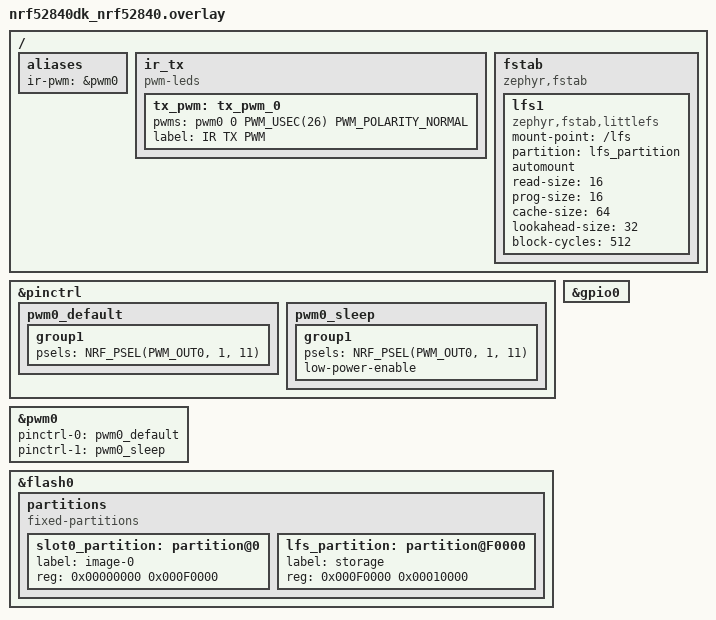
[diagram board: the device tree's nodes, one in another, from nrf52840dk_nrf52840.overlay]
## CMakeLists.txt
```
# CMakeLists.txt for IR Remote Control Project

cmake_minimum_required(VERSION 3.20.0)

find_package(Zephyr REQUIRED HINTS $ENV{ZEPHYR_BASE})
project(ir_remote_control)

# 包含目录
target_include_directories(app PRIVATE
    ${CMAKE_CURRENT_SOURCE_DIR}/include
)

# 源文件
target_sources(app PRIVATE
    src/main.c
    src/ir_hal.c
    src/irdb_protocol.c
    src/irdb_loader.c
    src/ir_service.c
    src/ir_learning.c
)

# 如果有Shell支持，添加学习应用示例
if(CONFIG_SHELL)
    target_sources(app PRIVATE
        src/ir_learning_app.c
    )
endif()
```

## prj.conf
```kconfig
#
# prj.conf - Zephyr项目配置
#

# 基本配置
CONFIG_HEAP_MEM_POOL_SIZE=16384
CONFIG_MAIN_STACK_SIZE=4096
CONFIG_SYSTEM_WORKQUEUE_STACK_SIZE=2048

# GPIO支持
CONFIG_GPIO=y

# PWM支持
CONFIG_PWM=y

# 日志系统
CONFIG_LOG=y
CONFIG_LOG_MODE_IMMEDIATE=y
CONFIG_PRINTK=y
CONFIG_CONSOLE=y
CONFIG_UART_CONSOLE=y

# 调试支持
CONFIG_DEBUG=y
CONFIG_DEBUG_INFO=y
CONFIG_ASSERT=y

# Shell命令行
CONFIG_SHELL=y
CONFIG_SHELL_BACKEND_SERIAL=y
CONFIG_SHELL_PROMPT_UART="ir> "
CONFIG_SHELL_CMD_BUFF_SIZE=128
CONFIG_SHELL_PRINTF_BUFF_SIZE=128

# 浮点数支持
CONFIG_FPU=y

# 动态内存分配
CONFIG_HEAP_MEM_POOL_SIZE=16384

# 文件系统支持（完整配置）
CONFIG_FILE_SYSTEM=y
CONFIG_FILE_SYSTEM_LITTLEFS=y

# Flash驱动支持（LittleFS需要）
CONFIG_FLASH=y
CONFIG_FLASH_MAP=y
CONFIG_FLASH_PAGE_LAYOUT=y

# NVS存储支持（替代方案，推荐用于简单存储）
CONFIG_NVS=y
CONFIG_MPU_ALLOW_FLASH_WRITE=y

# 网络支持（可选，默认禁用）
# CONFIG_NETWORKING=y
# CONFIG_NET_SOCKETS=y
# CONFIG_HTTP_CLIENT=y
```

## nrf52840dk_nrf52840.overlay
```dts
/*
 * nRF52840 IR设备树配置
 * 文件名: nrf52840dk_nrf52840.overlay
 */

/ {
    aliases {
        ir-pwm = &pwm0;
    };
    
    ir_tx: ir_tx {
        compatible = "pwm-leds";
        status = "okay";
        tx_pwm: tx_pwm_0 {
            pwms = <&pwm0 0 PWM_USEC(26) PWM_POLARITY_NORMAL>;
            label = "IR TX PWM";
        };
    };
    
    /* LittleFS挂载配置 */
    fstab {
        compatible = "zephyr,fstab";
        lfs1: lfs1 {
            compatible = "zephyr,fstab,littlefs";
            mount-point = "/lfs";
            partition = <&lfs_partition>;
            automount;
            read-size = <16>;
            prog-size = <16>;
            cache-size = <64>;
            lookahead-size = <32>;
            block-cycles = <512>;
        };
    };
};

&pinctrl {
    pwm0_default: pwm0_default {
        group1 {
            psels = <NRF_PSEL(PWM_OUT0, 1, 11)>;
        };
    };

    pwm0_sleep: pwm0_sleep {
        group1 {
            psels = <NRF_PSEL(PWM_OUT0, 1, 11)>;
            low-power-enable;
        };
    };
};

&pwm0 {
    status = "okay";
    pinctrl-0 = <&pwm0_default>;
    pinctrl-1 = <&pwm0_sleep>;
    pinctrl-names = "default", "sleep";
};

&gpio0 {
    status = "okay";
};

/* 删除现有的分区定义，重新定义 */
/delete-node/ &boot_partition;
/delete-node/ &slot0_partition;
/delete-node/ &slot1_partition;
/delete-node/ &storage_partition;

/* Flash分区配置 - 简化版本，不使用MCUboot */
&flash0 {
    partitions {
        compatible = "fixed-partitions";
        #address-cells = <1>;
        #size-cells = <1>;

        /* 应用程序区域 */
        slot0_partition: partition@0 {
            label = "image-0";
            reg = <0x00000000 0x000F0000>;  /* 960KB 用于应用 */
        };

        /* LittleFS存储分区 */
        lfs_partition: partition@F0000 {
            label = "storage";
            reg = <0x000F0000 0x00010000>;  /* 64KB 用于文件系统 */
        };
    };
};
```

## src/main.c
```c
/**
 * @file main.c
 * @brief IR遥控应用 - 使用IRDB数据库 + 自学习功能
 */

#include "ir_learning.h"
#include "ir_service.h"
#include <stdlib.h> // 添加：atoi
#include <string.h> // 添加：strcmp, strcpy
#include <zephyr/kernel.h>
#include <zephyr/logging/log.h>


LOG_MODULE_REGISTER(ir_app, LOG_LEVEL_INF);

/* Zephyr已经定义了ARRAY_SIZE，不需要重复定义 */

/* 嵌入式IRDB数据 - Samsung TV (7,7) */
static const char samsung_tv_7_7[] = "Power,1,7,7,2\n"
                                     "Source,1,7,7,1\n"
                                     "Menu,1,7,7,26\n"
                                     "Up,1,7,7,96\n"
                                     "Down,1,7,7,97\n"
                                     "Left,1,7,7,101\n"
                                     "Right,1,7,7,98\n"
                                     "Enter,1,7,7,104\n"
                                     "Back,1,7,7,88\n"
                                     "Vol+,1,7,7,7\n"
                                     "Vol-,1,7,7,11\n"
                                     "Mute,1,7,7,15\n"
                                     "Ch+,1,7,7,18\n"
                                     "Ch-,1,7,7,16\n"
                                     "1,1,7,7,4\n"
                                     "2,1,7,7,5\n"
                                     "3,1,7,7,6\n"
                                     "4,1,7,7,8\n"
                                     "5,1,7,7,9\n"
                                     "6,1,7,7,10\n"
                                     "7,1,7,7,12\n"
                                     "8,1,7,7,13\n"
                                     "9,1,7,7,14\n"
                                     "0,1,7,7,17\n";

/* Sony TV IRDB数据 */
static const char sony_tv[] = "Power,15,1,0,21\n"
                              "Vol+,15,1,0,18\n"
                              "Vol-,15,1,0,19\n"
                              "Ch+,15,1,0,16\n"
                              "Ch-,15,1,0,17\n"
                              "Mute,15,1,0,20\n"
                              "Input,15,1,0,37\n"
                              "1,15,1,0,0\n"
                              "2,15,1,0,1\n"
                              "3,15,1,0,2\n"
                              "4,15,1,0,3\n"
                              "5,15,1,0,4\n"
                              "6,15,1,0,5\n"
                              "7,15,1,0,6\n"
                              "8,15,1,0,7\n"
                              "9,15,1,0,8\n"
                              "0,15,1,0,9\n";

/* 接收回调 */
static void rx_callback(const irdb_entry_t *entry, void *user_data) {
  LOG_INF("Received: %s", entry->function_name);
  LOG_INF("  Protocol: %u, Device: %u.%u, Function: %u", entry->protocol,
          entry->device, entry->subdevice, entry->function);

  /* 根据接收到的命令执行操作 */
  if (strcmp(entry->function_name, "Power") == 0) {
    LOG_INF(">> Power button action");
  } else if (strcmp(entry->function_name, "Vol+") == 0) {
    LOG_INF(">> Volume up action");
  } else if (strcmp(entry->function_name, "Vol-") == 0) {
    LOG_INF(">> Volume down action");
  }
}

/* 发送测试 */
static void test_send(void) {
  LOG_INF("=== Send Test ===");

  const char *test_commands[] = {"Power", "Vol+", "Vol-", "Ch+", "Mute"};

  for (int i = 0; i < ARRAY_SIZE(test_commands); i++) {
    LOG_INF("Sending: %s", test_commands[i]);

    int ret = ir_service_send_command(test_commands[i], 1);
    if (ret < 0) {
      LOG_ERR("Failed to send %s: %d", test_commands[i], ret);
    }

    k_sleep(K_MSEC(500));
  }
}

/* 接收测试 */
static void test_receive(uint32_t duration_sec) {
  LOG_INF("=== Receive Test ===");
  LOG_INF("Point remote at receiver and press buttons...");

  int ret = ir_service_start_receive(rx_callback, NULL);
  if (ret < 0) {
    LOG_ERR("Failed to start receive: %d", ret);
    return;
  }

  k_sleep(K_SECONDS(duration_sec));

  ir_service_stop_receive();
  LOG_INF("Receive test completed");
}

/* 主函数 */
int main(void) {
  LOG_INF("========================================");
  LOG_INF("  IR Remote Control with IRDB");
  LOG_INF("  + Self-Learning Feature");
  LOG_INF("  nRF52840 + Zephyr RTOS");
  LOG_INF("========================================");

  /* 初始化服务 */
  int ret = ir_service_init();
  if (ret < 0) {
    LOG_ERR("Service init failed: %d", ret);
    return ret;
  }

  /* 初始化学习模块 */
  ret = ir_learning_init();
  if (ret < 0) {
    LOG_ERR("Learning init failed: %d", ret);
    return ret;
  }

  /* 方式1: 从嵌入式数据加载 */
  LOG_INF("Loading Samsung TV database (embedded)...");
  ret = ir_service_load_embedded_csv(samsung_tv_7_7, "Samsung", "TV");
  if (ret < 0) {
    LOG_ERR("Failed to load database: %d", ret);
    return ret;
  }

  /* 显示数据库信息 */
  char list_buf[1024];
  ir_service_list_functions(list_buf, sizeof(list_buf));
  LOG_INF("\n%s", list_buf);

  k_sleep(K_SECONDS(2));

  /* 运行测试 */
  while (1) {
    LOG_INF("\n>>> Test Cycle Start <<<\n");

    /* 发送测试 */
    test_send();
    k_sleep(K_SECONDS(2));

    /* 接收测试 */
    test_receive(30);
    k_sleep(K_SECONDS(2));

    LOG_INF("\n>>> Test Cycle Complete <<<\n");

/* 可选: 切换到Sony遥控器 */
#if 0
        LOG_INF("Switching to Sony TV database...");
        ir_service_load_embedded_csv(sony_tv, "Sony", "TV");
        ir_service_list_functions(list_buf, sizeof(list_buf));
        LOG_INF("\n%s", list_buf);
#endif
  }

  return 0;
}

/* Shell命令接口 */
#ifdef CONFIG_SHELL

#include <zephyr/shell/shell.h>

/* 加载数据库命令 */
static int cmd_load(const struct shell *shell, size_t argc, char **argv) {
  if (argc < 2) {
    shell_error(shell, "Usage: ir load <samsung|sony>");
    return -EINVAL;
  }

  int ret;
  if (strcmp(argv[1], "samsung") == 0) {
    ret = ir_service_load_embedded_csv(samsung_tv_7_7, "Samsung", "TV");
  } else if (strcmp(argv[1], "sony") == 0) {
    ret = ir_service_load_embedded_csv(sony_tv, "Sony", "TV");
  } else {
    shell_error(shell, "Unknown remote: %s", argv[1]);
    return -EINVAL;
  }

  if (ret == 0) {
    shell_print(shell, "Database loaded successfully");
  } else {
    shell_error(shell, "Failed to load: %d", ret);
  }

  return ret;
}

/* 发送命令 */
static int cmd_send(const struct shell *shell, size_t argc, char **argv) {
  if (argc < 2) {
    shell_error(shell, "Usage: ir send <function> [repeat]");
    return -EINVAL;
  }

  const char *function = argv[1];
  uint32_t repeat = argc > 2 ? atoi(argv[2]) : 1;

  shell_print(shell, "Sending: %s (x%u)", function, repeat);

  int ret = ir_service_send_command(function, repeat);
  if (ret < 0) {
    shell_error(shell, "Send failed: %d", ret);
    return ret;
  }

  shell_print(shell, "Sent successfully");
  return 0;
}

/* 接收命令 */
static int cmd_receive(const struct shell *shell, size_t argc, char **argv) {
  uint32_t duration = argc > 1 ? atoi(argv[1]) : 10;

  shell_print(shell, "Receiving for %u seconds...", duration);

  int ret = ir_service_start_receive(rx_callback, NULL);
  if (ret < 0) {
    shell_error(shell, "Failed to start: %d", ret);
    return ret;
  }

  k_sleep(K_SECONDS(duration));
  ir_service_stop_receive();

  shell_print(shell, "Receive completed");
  return 0;
}

/* 列出功能 */
static int cmd_list(const struct shell *shell, size_t argc, char **argv) {
  char buf[1024];

  int ret = ir_service_list_functions(buf, sizeof(buf));
  if (ret < 0) {
    shell_error(shell, "No database loaded");
    return ret;
  }

  shell_print(shell, "%s", buf);
  return 0;
}

/* 从文件加载（需要文件系统支持） */
#ifdef CONFIG_FILE_SYSTEM
static int cmd_load_file(const struct shell *shell, size_t argc, char **argv) {
  if (argc < 4) {
    shell_error(
        shell,
        "Usage: ir loadfile <manufacturer> <device_type> <device,subdevice>");
    shell_error(shell, "Example: ir loadfile Samsung TV 7,7");
    return -EINVAL;
  }

  const char *manufacturer = argv[1];
  const char *device_type = argv[2];

  uint8_t device, subdevice;
  if (sscanf(argv[3], "%hhu,%hhu", &device, &subdevice) != 2) {
    shell_error(shell, "Invalid device,subdevice format");
    return -EINVAL;
  }

  ir_service_config_t config = {.load_method = IRDB_LOAD_FILESYSTEM,
                                .device = device,
                                .subdevice = subdevice};

  strncpy(config.manufacturer, manufacturer, sizeof(config.manufacturer) - 1);
  strncpy(config.device_type, device_type, sizeof(config.device_type) - 1);

  shell_print(shell, "Loading: %s/%s/%u,%u.csv", manufacturer, device_type,
              device, subdevice);

  int ret = ir_service_load_remote(&config);
  if (ret < 0) {
    shell_error(shell, "Load failed: %d", ret);
    return ret;
  }

  shell_print(shell, "Loaded successfully");
  return 0;
}
#endif

SHELL_STATIC_SUBCMD_SET_CREATE(
    ir_cmds, SHELL_CMD(load, NULL, "Load embedded database", cmd_load),
    SHELL_CMD(send, NULL, "Send IR command", cmd_send),
    SHELL_CMD(receive, NULL, "Receive IR signals", cmd_receive),
    SHELL_CMD(list, NULL, "List functions", cmd_list),
#ifdef CONFIG_FILE_SYSTEM
    SHELL_CMD(loadfile, NULL, "Load from file", cmd_load_file),
#endif
    SHELL_SUBCMD_SET_END);

SHELL_CMD_REGISTER(ir, &ir_cmds, "IR remote control (IRDB)", NULL);

#endif /* CONFIG_SHELL */
```

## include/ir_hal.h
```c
/**
 * @file ir_hal.h
 * @brief IR硬件抽象层 - nRF52840
 */

#ifndef IR_HAL_H
#define IR_HAL_H

#include <zephyr/device.h>
#include <zephyr/drivers/gpio.h>
#include <zephyr/drivers/pwm.h>
#include <zephyr/kernel.h>

/* 配置参数 */
#define IR_TX_NODE DT_NODELABEL(tx_pwm)
#define IR_RX_PIN 12           // P0.14 用于IR接收
#define IR_CARRIER_FREQ 38000  // 38kHz载波
#define IR_PWM_DUTY 33         // 33%占空比
#define IR_MAX_PULSE_US 100000 // 最大脉冲宽度100ms
#define IR_TIMER_FREQ 1000000  // 1MHz定时器频率

/* IR脉冲结构 */
typedef struct {
  uint32_t duration_us; // 持续时间(微秒)
  bool is_mark;         // true=mark(载波), false=space(无载波)
} ir_pulse_t;

/* IR接收回调 */
typedef void (*ir_rx_callback_t)(ir_pulse_t *pulse, void *user_data);

/* HAL初始化 */
int ir_hal_init(void);

/* 发送接口 */
int ir_hal_tx_start(uint32_t carrier_freq);
int ir_hal_tx_stop(void);
int ir_hal_tx_pulse(uint32_t duration_us, bool is_mark);

/* 接收接口 */
int ir_hal_rx_start(ir_rx_callback_t callback, void *user_data);
int ir_hal_rx_stop(void);

#endif /* IR_HAL_H */
```

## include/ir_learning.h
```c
/**
 * @file ir_learning.h
 * @brief IR自学习模块 - 录制和重放任意红外信号
 */

#ifndef IR_LEARNING_H
#define IR_LEARNING_H

#include <stdbool.h>
#include <stddef.h>
#include <stdint.h>

/* 学习的信号最大长度 */
#define IR_LEARNING_MAX_EDGES 512
#define IR_LEARNING_MAX_DURATION_US 100000

/* 学习信号结构 */
typedef struct {
  char name[32];              // 信号名称
  uint32_t *timings;          // 时序数据数组 (微秒)
  uint16_t timing_count;      // 时序数量
  uint32_t carrier_freq;      // 检测到的载波频率
  uint32_t total_duration_us; // 总时长
  bool valid;                 // 是否有效
} ir_learned_signal_t;

/* 学习回调 - 学习过程中的状态通知 */
typedef enum {
  IR_LEARN_IDLE,      // 空闲
  IR_LEARN_WAITING,   // 等待信号
  IR_LEARN_RECEIVING, // 接收中
  IR_LEARN_COMPLETED, // 完成
  IR_LEARN_TIMEOUT,   // 超时
  IR_LEARN_ERROR      // 错误
} ir_learn_status_t;

typedef void (*ir_learn_callback_t)(ir_learn_status_t status,
                                    const ir_learned_signal_t *signal,
                                    void *user_data);

/* 初始化学习模块 */
int ir_learning_init(void);

/* 开始学习模式 */
int ir_learning_start(const char *signal_name, ir_learn_callback_t callback,
                      void *user_data, uint32_t timeout_ms);

/* 停止学习 */
int ir_learning_stop(void);

/* 重放学习的信号 */
int ir_learning_replay(const ir_learned_signal_t *signal,
                       uint32_t repeat_count);

/* 保存学习的信号到存储 */
int ir_learning_save(const ir_learned_signal_t *signal, const char *name);

/* 从存储加载信号 */
int ir_learning_load(ir_learned_signal_t *signal, const char *name);

/* 删除已保存的信号 */
int ir_learning_delete(const char *name);

/* 列出所有已保存的信号 */
int ir_learning_list(char *buf, size_t buf_size);

/* 导出为原始格式 (用于调试) */
int ir_learning_export_raw(const ir_learned_signal_t *signal, char *buf,
                           size_t buf_size);

/* 从原始格式导入 */
int ir_learning_import_raw(ir_learned_signal_t *signal, const char *raw_data);

void test_ir_learning(void);

/* 分析信号特征 */
typedef struct {
  uint32_t avg_mark;       // 平均mark时长
  uint32_t avg_space;      // 平均space时长
  uint32_t min_pulse;      // 最短脉冲
  uint32_t max_pulse;      // 最长脉冲
  uint32_t pulse_count;    // 脉冲数量
  uint32_t estimated_freq; // 估计的载波频率
} ir_signal_analysis_t;

int ir_learning_analyze(const ir_learned_signal_t *signal,
                        ir_signal_analysis_t *analysis);

/* 比较两个信号的相似度 (0-100%) */
int ir_learning_compare(const ir_learned_signal_t *sig1,
                        const ir_learned_signal_t *sig2, uint8_t *similarity);

#endif /* IR_LEARNING_H */
```

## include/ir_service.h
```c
/**
 * @file ir_service.h
 * @brief IR服务层 - 整合HAL、IRDB协议和加载器
 */

#ifndef IR_SERVICE_H
#define IR_SERVICE_H

#include "ir_hal.h"
#include "irdb_loader.h"
#include "irdb_protocol.h"
#include <stddef.h>


/* IR服务配置 */
typedef struct {
  irdb_load_method_t load_method;
  char manufacturer[64];
  char device_type[64];
  uint8_t device;
  uint8_t subdevice;
} ir_service_config_t;

/* IR服务初始化 */
int ir_service_init(void);

/* 加载遥控器数据库 */
int ir_service_load_remote(const ir_service_config_t *config);

/* 从嵌入式数据加载 */
int ir_service_load_embedded_csv(const char *csv_data, const char *manufacturer,
                                 const char *device_type);

/* 发送命令（通过功能名） */
int ir_service_send_command(const char *function_name, uint32_t repeat);

/* 发送原始IRDB条目 */
int ir_service_send_entry(const irdb_entry_t *entry, uint32_t repeat);

/* 接收回调 */
typedef void (*ir_service_rx_callback_t)(const irdb_entry_t *entry,
                                         void *user_data);

/* 启动接收 */
int ir_service_start_receive(ir_service_rx_callback_t callback,
                             void *user_data);

/* 停止接收 */
int ir_service_stop_receive(void);

/* 列出当前数据库的所有功能 */
int ir_service_list_functions(char *buf, size_t buf_size);

/* 获取当前数据库信息 */
const irdb_database_t *ir_service_get_database(void);

#endif /* IR_SERVICE_H */
```

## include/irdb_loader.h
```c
/**
 * @file irdb_loader.h
 * @brief IRDB数据加载器 - 支持多种加载方式
 */

#ifndef IRDB_LOADER_H
#define IRDB_LOADER_H

#include "irdb_protocol.h"
#include <stddef.h>


/* 加载方式 */
typedef enum {
  IRDB_LOAD_EMBEDDED,   // 嵌入式存储（编译时包含）
  IRDB_LOAD_FILESYSTEM, // 从文件系统加载
  IRDB_LOAD_HTTP,       // 从HTTP服务器加载（需要网络）
  IRDB_LOAD_EXTERNAL,   // 外部存储（SD卡等）
} irdb_load_method_t;

/* IRDB路径构建 */
void irdb_build_path(char *path_out, size_t path_size, const char *manufacturer,
                     const char *device_type, uint8_t device,
                     uint8_t subdevice);

/* 从嵌入式数据加载 */
int irdb_load_embedded(irdb_database_t *db, const char *csv_data);

/* 从文件系统加载 */
int irdb_load_from_file(irdb_database_t *db, const char *filepath);

/* 从HTTP加载（需要网络支持） */
int irdb_load_from_http(irdb_database_t *db, const char *manufacturer,
                        const char *device_type, uint8_t device,
                        uint8_t subdevice);

/* 缓存管理 */
typedef struct {
  char path[128];
  irdb_database_t database;
  uint32_t last_access;
  bool valid;
} irdb_cache_entry_t;

#define IRDB_CACHE_SIZE 4

int irdb_cache_get(const char *path, irdb_database_t **db_out);
int irdb_cache_put(const char *path, const irdb_database_t *db);
void irdb_cache_clear(void);

#endif /* IRDB_LOADER_H */
```

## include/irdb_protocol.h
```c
/**
 * @file irdb_protocol.h
 * @brief IRDB协议定义和CSV解析器
 *
 * IRDB使用 protocol,device,subdevice,function 格式存储IR码
 */

#ifndef IRDB_PROTOCOL_H
#define IRDB_PROTOCOL_H

#include <stdbool.h>
#include <stdint.h>


/* IRDB协议编号 */
typedef enum {
  IRDB_PROTOCOL_NEC1 = 1,
  IRDB_PROTOCOL_NEC2 = 2,
  IRDB_PROTOCOL_RC5 = 4,
  IRDB_PROTOCOL_RC6 = 5,
  IRDB_PROTOCOL_SONY12 = 15,
  IRDB_PROTOCOL_SONY15 = 16,
  IRDB_PROTOCOL_SONY20 = 17,
  IRDB_PROTOCOL_SAMSUNG32 = 20,
  IRDB_PROTOCOL_SAMSUNG36 = 21,
} irdb_protocol_id_t;

/* IRDB条目 */
typedef struct {
  char function_name[32]; // 功能名称 (如 "Power", "Vol+")
  uint16_t protocol;      // 协议编号
  uint16_t device;        // 设备码
  uint16_t subdevice;     // 子设备码
  uint16_t function;      // 功能码
} irdb_entry_t;

/* IRDB数据库 */
typedef struct {
  char manufacturer[64]; // 制造商
  char device_type[64];  // 设备类型
  irdb_entry_t *entries; // 条目数组
  uint32_t entry_count;  // 条目数量
} irdb_database_t;

/* 协议参数表 */
typedef struct {
  irdb_protocol_id_t protocol_id;
  const char *name;
  uint32_t frequency;     // 载波频率(Hz)
  uint32_t duty_cycle;    // 占空比(%)
  uint32_t header_mark;   // 引导标记(us)
  uint32_t header_space;  // 引导间隔(us)
  uint32_t bit_mark;      // 位标记(us)
  uint32_t bit_0_space;   // 0位间隔(us)
  uint32_t bit_1_space;   // 1位间隔(us)
  uint32_t trailer_mark;  // 结束标记(us)
  uint32_t gap;           // 重复间隔(us)
  uint8_t device_bits;    // 设备码位数
  uint8_t subdevice_bits; // 子设备码位数
  uint8_t function_bits;  // 功能码位数
  bool toggle_bit;        // 是否有toggle位
} irdb_protocol_params_t;

/* 协议参数查询 */
const irdb_protocol_params_t *
irdb_get_protocol_params(irdb_protocol_id_t protocol);

/* CSV解析 */
int irdb_parse_csv(const char *csv_data, irdb_database_t *db);

/* 释放数据库 */
void irdb_free_database(irdb_database_t *db);

/* 查找功能 */
const irdb_entry_t *irdb_find_function(const irdb_database_t *db,
                                       const char *function_name);

/* 编码为原始数据 */
int irdb_encode_to_raw(const irdb_entry_t *entry, uint32_t *timings_out,
                       uint32_t *length_out, uint32_t max_length);

/* 解码原始数据 */
int irdb_decode_from_raw(const irdb_database_t *db, const uint32_t *timings,
                         uint32_t length, irdb_entry_t *entry_out);

#endif /* IRDB_PROTOCOL_H */
```

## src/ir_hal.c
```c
/**
 * @file ir_hal.c
 * @brief IR硬件抽象层实现 - nRF52840
 */

#include "ir_hal.h"
#include <zephyr/drivers/gpio.h>
#include <zephyr/logging/log.h>

LOG_MODULE_REGISTER(ir_hal, LOG_LEVEL_INF);

/* PWM设备 */
static const struct pwm_dt_spec pwm_ir = PWM_DT_SPEC_GET(IR_TX_NODE);

/* GPIO设备 - 使用设备树方式获取 */
#define RX_GPIO_NODE DT_NODELABEL(gpio1)
static const struct device *gpio_dev = DEVICE_DT_GET(RX_GPIO_NODE);

/* GPIO回调结构 */
static struct gpio_callback gpio_cb;

/* 接收状态 */
static struct {
  ir_rx_callback_t callback;
  void *user_data;
  uint32_t last_edge_us;
  bool last_state;
  bool active;
} rx_state;

/* GPIO中断处理 - 接收边沿检测 */
static void gpio_callback_handler(const struct device *dev,
                                  struct gpio_callback *cb, uint32_t pins) {
  /* 安全检查 */
  if (!rx_state.active) {
    return;
  }

  if (!dev || dev != gpio_dev) {
    return;
  }

  uint32_t now_us = k_cyc_to_us_floor32(k_cycle_get_32());
  int current_state = gpio_pin_get(gpio_dev, IR_RX_PIN);

  /* 检查GPIO读取是否成功 */
  if (current_state < 0) {
    return;
  }

  if (rx_state.last_edge_us > 0) {
    uint32_t duration;

    /* 处理32位计数器溢出 */
    if (now_us >= rx_state.last_edge_us) {
      duration = now_us - rx_state.last_edge_us;
    } else {
      /* 溢出情况 */
      duration = (UINT32_MAX - rx_state.last_edge_us) + now_us + 1;
    }

    if (duration > 0 && duration < IR_MAX_PULSE_US) {
      ir_pulse_t pulse = {
          .duration_us = duration,
          .is_mark = !rx_state.last_state // 上一个状态
      };

      if (rx_state.callback) {
        rx_state.callback(&pulse, rx_state.user_data);
      }
    }
  }

  rx_state.last_edge_us = now_us;
  rx_state.last_state = (current_state != 0);
}

/* HAL初始化 */
int ir_hal_init(void) {
  int ret;

  LOG_INF("Initializing IR HAL...");

  /* 检查PWM设备 */
  if (!device_is_ready(pwm_ir.dev)) {
    LOG_ERR("PWM device not ready");
    return -ENODEV;
  }
  LOG_DBG("PWM device ready");

  /* 检查GPIO设备 */
  if (!gpio_dev) {
    LOG_ERR("GPIO device is NULL");
    return -ENODEV;
  }

  if (!device_is_ready(gpio_dev)) {
    LOG_ERR("GPIO device not ready");
    return -ENODEV;
  }
  LOG_DBG("GPIO device ready");

  /* 配置RX GPIO为输入，带上拉 */
  ret = gpio_pin_configure(gpio_dev, IR_RX_PIN, GPIO_INPUT | GPIO_PULL_UP);
  if (ret < 0) {
    LOG_ERR("Failed to configure RX pin %d: %d", IR_RX_PIN, ret);
    return ret;
  }
  LOG_DBG("RX pin %d configured", IR_RX_PIN);

  /* 禁用GPIO中断（初始状态） */
  ret = gpio_pin_interrupt_configure(gpio_dev, IR_RX_PIN, GPIO_INT_DISABLE);
  if (ret < 0) {
    LOG_ERR("Failed to configure interrupt: %d", ret);
    return ret;
  }

  /* 初始化GPIO回调 */
  gpio_init_callback(&gpio_cb, gpio_callback_handler, BIT(IR_RX_PIN));

  ret = gpio_add_callback(gpio_dev, &gpio_cb);
  if (ret < 0) {
    LOG_ERR("Failed to add callback: %d", ret);
    return ret;
  }
  LOG_DBG("GPIO callback added");

  /* 初始化接收状态 */
  memset(&rx_state, 0, sizeof(rx_state));

  /* 确保PWM初始关闭 */
  ret = pwm_set_dt(&pwm_ir, 0, 0);
  if (ret < 0) {
    LOG_WRN("Failed to stop PWM initially: %d", ret);
  }

  LOG_INF("IR HAL initialized successfully");
  return 0;
}

/* 启动发送 - 配置载波频率 */
int ir_hal_tx_start(uint32_t carrier_freq) {
  uint32_t period_ns = NSEC_PER_SEC / carrier_freq;
  uint32_t pulse_ns = period_ns * IR_PWM_DUTY / 100;

  int ret = pwm_set_dt(&pwm_ir, period_ns, pulse_ns);
  if (ret < 0) {
    LOG_ERR("Failed to start PWM: %d", ret);
    return ret;
  }

  LOG_DBG("TX started: %u Hz", carrier_freq);
  return 0;
}

/* 停止发送 */
int ir_hal_tx_stop(void) {
  pwm_set_dt(&pwm_ir, 0, 0);
  LOG_DBG("TX stopped");
  return 0;
}

/* 发送单个脉冲 */
int ir_hal_tx_pulse(uint32_t duration_us, bool is_mark) {
  if (is_mark) {
    /* Mark: 恢复PWM输出 - 不需要重新配置，PWM保持运行 */
    /* nRF52840 PWM特性：一旦配置就持续输出 */
  } else {
    /* Space: 暂时禁用PWM */
    pwm_set_dt(&pwm_ir, 0, 0);
  }

  k_busy_wait(duration_us);

  /* 如果是space后，恢复PWM为下一个mark做准备 */
  if (!is_mark) {
    uint32_t period_ns = NSEC_PER_SEC / IR_CARRIER_FREQ;
    uint32_t pulse_ns = period_ns * IR_PWM_DUTY / 100;
    pwm_set_dt(&pwm_ir, period_ns, pulse_ns);
  }

  return 0;
}

/* 启动接收 */
int ir_hal_rx_start(ir_rx_callback_t callback, void *user_data) {
  if (!callback) {
    return -EINVAL;
  }

  rx_state.callback = callback;
  rx_state.user_data = user_data;
  rx_state.last_edge_us = 0;
  rx_state.last_state = false;
  rx_state.active = true;

  /* 启用双边沿中断 */
  int ret =
      gpio_pin_interrupt_configure(gpio_dev, IR_RX_PIN, GPIO_INT_EDGE_BOTH);
  if (ret < 0) {
    LOG_ERR("Failed to enable RX interrupt: %d", ret);
    return ret;
  }

  LOG_INF("RX started");
  return 0;
}

/* 停止接收 */
int ir_hal_rx_stop(void) {
  rx_state.active = false;
  gpio_pin_interrupt_configure(gpio_dev, IR_RX_PIN, GPIO_INT_DISABLE);

  LOG_INF("RX stopped");
  return 0;
}
```

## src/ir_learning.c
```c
/**
 * @file ir_learning.c
 * @brief IR自学习模块实现
 */

#include "ir_learning.h"
#include "ir_hal.h"
#include <stdlib.h>
#include <string.h>
#include <zephyr/kernel.h>
#include <zephyr/logging/log.h>


#ifdef CONFIG_FILE_SYSTEM
#include <zephyr/fs/fs.h>
#endif

LOG_MODULE_REGISTER(ir_learning, LOG_LEVEL_INF);

#define LEARNING_TIMEOUT_DEFAULT_MS 5000
#define SIGNAL_END_TIMEOUT_MS 150
#define MIN_PULSE_US 50
#define LEARNING_STORAGE_PATH "/lfs/ir_learned"

/* 学习状态 */
static struct {
  ir_learned_signal_t current_signal;
  ir_learn_callback_t callback;
  void *user_data;
  struct k_timer timeout_timer;
  struct k_timer end_timer;
  bool active;
  uint32_t edge_count;
  uint32_t start_time_us;
} learn_state;

/* 信号结束检测定时器 */
static void signal_end_handler(struct k_timer *timer) {
  if (!learn_state.active || learn_state.edge_count == 0) {
    return;
  }

  LOG_INF("Signal capture completed: %u edges", learn_state.edge_count);

  learn_state.current_signal.timing_count = learn_state.edge_count;
  learn_state.current_signal.valid = true;
  learn_state.active = false;

  /* 停止HAL接收 */
  ir_hal_rx_stop();

  /* 通知完成 */
  if (learn_state.callback) {
    learn_state.callback(IR_LEARN_COMPLETED, &learn_state.current_signal,
                         learn_state.user_data);
  }
}

/* 学习超时处理 */
static void learning_timeout_handler(struct k_timer *timer) {
  if (!learn_state.active) {
    return;
  }

  LOG_WRN("Learning timeout");

  learn_state.active = false;
  ir_hal_rx_stop();

  if (learn_state.callback) {
    learn_state.callback(IR_LEARN_TIMEOUT, NULL, learn_state.user_data);
  }
}

/* HAL接收回调 - 记录时序 */
static void learning_rx_callback(ir_pulse_t *pulse, void *user_data) {
  /* 安全检查 */
  if (!pulse) {
    LOG_ERR("Pulse is NULL");
    return;
  }

  if (!learn_state.active) {
    return;
  }

  /* 过滤过短的脉冲（噪声） */
  if (pulse->duration_us < MIN_PULSE_US) {
    return;
  }

  /* 关键检查：缓冲区是否存在 */
  if (!learn_state.current_signal.timings) {
    LOG_ERR("Timing buffer is NULL - learning not initialized!");
    /* 尝试恢复：停止学习 */
    learn_state.active = false;
    ir_hal_rx_stop();
    if (learn_state.callback) {
      learn_state.callback(IR_LEARN_ERROR, NULL, learn_state.user_data);
    }
    return;
  }

  /* 第一个脉冲 - 开始录制 */
  if (learn_state.edge_count == 0) {
    LOG_INF("Signal detected, recording...");
    learn_state.start_time_us = k_cyc_to_us_floor32(k_cycle_get_32());

    if (learn_state.callback) {
      learn_state.callback(IR_LEARN_RECEIVING, NULL, learn_state.user_data);
    }
  }

  /* 检查是否超出缓冲区 */
  if (learn_state.edge_count >= IR_LEARNING_MAX_EDGES) {
    LOG_ERR("Buffer overflow (%u edges), stopping", learn_state.edge_count);
    k_timer_stop(&learn_state.end_timer);
    signal_end_handler(NULL);
    return;
  }

  /* 记录时序 */
  learn_state.current_signal.timings[learn_state.edge_count++] =
      pulse->duration_us;

  /* 调试：每10个脉冲打印一次 */
  if (learn_state.edge_count % 10 == 0) {
    LOG_DBG("Recorded %u edges", learn_state.edge_count);
  }

  /* 重置信号结束定时器 */
  k_timer_start(&learn_state.end_timer, K_MSEC(SIGNAL_END_TIMEOUT_MS),
                K_NO_WAIT);
}

/* 初始化学习模块 */
int ir_learning_init(void) {
  memset(&learn_state, 0, sizeof(learn_state));

  /* 初始化定时器 */
  k_timer_init(&learn_state.timeout_timer, learning_timeout_handler, NULL);
  k_timer_init(&learn_state.end_timer, signal_end_handler, NULL);

  /* 分配时序缓冲区 - 关键！必须在这里分配 */
  learn_state.current_signal.timings =
      k_malloc(IR_LEARNING_MAX_EDGES * sizeof(uint32_t));

  if (!learn_state.current_signal.timings) {
    LOG_ERR("Failed to allocate timing buffer");
    return -ENOMEM;
  }

  /* 清零缓冲区 */
  memset(learn_state.current_signal.timings, 0,
         IR_LEARNING_MAX_EDGES * sizeof(uint32_t));

#ifdef CONFIG_FILE_SYSTEM
  /* 创建存储目录 */
  struct fs_dir_t dir;
  fs_dir_t_init(&dir);
  int ret = fs_opendir(&dir, LEARNING_STORAGE_PATH);
  if (ret < 0) {
    ret = fs_mkdir(LEARNING_STORAGE_PATH);
    if (ret < 0 && ret != -EEXIST) {
      LOG_WRN("Failed to create storage directory: %d", ret);
    }
  } else {
    fs_closedir(&dir);
  }
#endif

  LOG_INF("IR Learning initialized, buffer at %p",
          (void *)learn_state.current_signal.timings);
  return 0;
}

/* 开始学习 */
int ir_learning_start(const char *signal_name, ir_learn_callback_t callback,
                      void *user_data, uint32_t timeout_ms) {
  if (learn_state.active) {
    LOG_ERR("Learning already in progress");
    return -EBUSY;
  }

  /* 检查缓冲区是否已分配 */
  if (!learn_state.current_signal.timings) {
    LOG_ERR("Learning not initialized! Call ir_learning_init() first");
    return -EINVAL;
  }

  /* 重置信号数据（但保留timings指针） */
  uint32_t *timings_backup = learn_state.current_signal.timings;
  memset(&learn_state.current_signal, 0, sizeof(ir_learned_signal_t));
  learn_state.current_signal.timings = timings_backup;

  /* 清零缓冲区内容 */
  memset(learn_state.current_signal.timings, 0,
         IR_LEARNING_MAX_EDGES * sizeof(uint32_t));

  learn_state.edge_count = 0;

  if (signal_name) {
    strncpy(learn_state.current_signal.name, signal_name,
            sizeof(learn_state.current_signal.name) - 1);
  }

  learn_state.callback = callback;
  learn_state.user_data = user_data;
  learn_state.active = true;

  LOG_DBG("Learning buffer check: timings=%p, count=%u",
          (void *)learn_state.current_signal.timings, learn_state.edge_count);

  /* 启动HAL接收 */
  int ret = ir_hal_rx_start(learning_rx_callback, NULL);
  if (ret < 0) {
    LOG_ERR("Failed to start RX: %d", ret);
    learn_state.active = false;
    return ret;
  }

  /* 启动超时定时器 */
  uint32_t timeout = timeout_ms > 0 ? timeout_ms : LEARNING_TIMEOUT_DEFAULT_MS;
  k_timer_start(&learn_state.timeout_timer, K_MSEC(timeout), K_NO_WAIT);

  LOG_INF("Learning started: '%s', timeout: %u ms",
          signal_name ? signal_name : "(unnamed)", timeout);

  if (callback) {
    callback(IR_LEARN_WAITING, NULL, user_data);
  }

  return 0;
}

/* 停止学习 */
int ir_learning_stop(void) {
  if (!learn_state.active) {
    return 0;
  }

  learn_state.active = false;
  k_timer_stop(&learn_state.timeout_timer);
  k_timer_stop(&learn_state.end_timer);
  ir_hal_rx_stop();

  LOG_INF("Learning stopped");
  return 0;
}

/* 重放学习的信号 */
int ir_learning_replay(const ir_learned_signal_t *signal,
                       uint32_t repeat_count) {
  if (!signal || !signal->valid) {
    LOG_ERR("Invalid signal");
    return -EINVAL;
  }

  LOG_INF("Replaying signal: '%s' (%u edges, %u repeats)", signal->name,
          signal->timing_count, repeat_count);

  /* 使用检测到的载波频率，默认38kHz */
  uint32_t carrier = signal->carrier_freq > 0 ? signal->carrier_freq : 38000;

  int ret = ir_hal_tx_start(carrier);
  if (ret < 0) {
    return ret;
  }

  for (uint32_t r = 0; r < repeat_count; r++) {
    /* 发送所有时序 */
    for (uint16_t i = 0; i < signal->timing_count; i++) {
      bool is_mark = (i % 2 == 0); // 偶数索引为mark
      ir_hal_tx_pulse(signal->timings[i], is_mark);
    }

    /* 重复间隔 */
    if (r < repeat_count - 1) {
      k_usleep(108000); // 标准间隔
    }
  }

  ir_hal_tx_stop();

  LOG_INF("Replay completed");
  return 0;
}

#ifdef CONFIG_FILE_SYSTEM
/* 保存学习的信号 */
int ir_learning_save(const ir_learned_signal_t *signal, const char *name) {
  if (!signal || !signal->valid || !name) {
    return -EINVAL;
  }

  char filepath[128];
  snprintf(filepath, sizeof(filepath), "%s/%s.dat", LEARNING_STORAGE_PATH,
           name);

  struct fs_file_t file;
  fs_file_t_init(&file);

  int ret = fs_open(&file, filepath, FS_O_CREATE | FS_O_WRITE | FS_O_TRUNC);
  if (ret < 0) {
    LOG_ERR("Failed to open file: %d", ret);
    return ret;
  }

  /* 写入头部信息 */
  fs_write(&file, signal->name, sizeof(signal->name));
  fs_write(&file, &signal->timing_count, sizeof(signal->timing_count));
  fs_write(&file, &signal->carrier_freq, sizeof(signal->carrier_freq));
  fs_write(&file, &signal->total_duration_us,
           sizeof(signal->total_duration_us));

  /* 写入时序数据 */
  fs_write(&file, signal->timings, signal->timing_count * sizeof(uint32_t));

  fs_close(&file);

  LOG_INF("Signal saved: %s (%u bytes)", name,
          signal->timing_count * sizeof(uint32_t));
  return 0;
}

/* 从存储加载信号 */
int ir_learning_load(ir_learned_signal_t *signal, const char *name) {
  if (!signal || !name) {
    return -EINVAL;
  }

  char filepath[128];
  snprintf(filepath, sizeof(filepath), "%s/%s.dat", LEARNING_STORAGE_PATH,
           name);

  struct fs_file_t file;
  fs_file_t_init(&file);

  int ret = fs_open(&file, filepath, FS_O_READ);
  if (ret < 0) {
    LOG_ERR("Failed to open file: %d", ret);
    return ret;
  }

  /* 读取头部 */
  fs_read(&file, signal->name, sizeof(signal->name));
  fs_read(&file, &signal->timing_count, sizeof(signal->timing_count));
  fs_read(&file, &signal->carrier_freq, sizeof(signal->carrier_freq));
  fs_read(&file, &signal->total_duration_us, sizeof(signal->total_duration_us));

  /* 分配并读取时序数据 */
  if (!signal->timings) {
    signal->timings = k_malloc(IR_LEARNING_MAX_EDGES * sizeof(uint32_t));
    if (!signal->timings) {
      fs_close(&file);
      return -ENOMEM;
    }
  }

  fs_read(&file, signal->timings, signal->timing_count * sizeof(uint32_t));

  fs_close(&file);
  signal->valid = true;

  LOG_INF("Signal loaded: %s", name);
  return 0;
}

/* 删除信号 */
int ir_learning_delete(const char *name) {
  if (!name) {
    return -EINVAL;
  }

  char filepath[128];
  snprintf(filepath, sizeof(filepath), "%s/%s.dat", LEARNING_STORAGE_PATH,
           name);

  int ret = fs_unlink(filepath);
  if (ret < 0) {
    LOG_ERR("Failed to delete: %d", ret);
    return ret;
  }

  LOG_INF("Signal deleted: %s", name);
  return 0;
}

/* 列出所有信号 */
int ir_learning_list(char *buf, size_t buf_size) {
  if (!buf) {
    return -EINVAL;
  }

  struct fs_dir_t dir;
  fs_dir_t_init(&dir);

  int ret = fs_opendir(&dir, LEARNING_STORAGE_PATH);
  if (ret < 0) {
    return ret;
  }

  size_t offset = 0;
  offset += snprintf(buf + offset, buf_size - offset, "Learned signals:\n");

  struct fs_dirent entry;
  while (fs_readdir(&dir, &entry) == 0 && entry.name[0] != '\0') {
    if (entry.type == FS_DIR_ENTRY_FILE) {
      /* 去除 .dat 后缀 */
      char *dot = strrchr(entry.name, '.');
      if (dot)
        *dot = '\0';

      offset += snprintf(buf + offset, buf_size - offset, "  %s\n", entry.name);
    }
  }

  fs_closedir(&dir);
  return 0;
}
#else
int ir_learning_save(const ir_learned_signal_t *signal, const char *name) {
  LOG_ERR("File system not enabled");
  return -ENOTSUP;
}

int ir_learning_load(ir_learned_signal_t *signal, const char *name) {
  LOG_ERR("File system not enabled");
  return -ENOTSUP;
}

int ir_learning_delete(const char *name) {
  LOG_ERR("File system not enabled");
  return -ENOTSUP;
}

int ir_learning_list(char *buf, size_t buf_size) {
  if (buf && buf_size > 0) {
    snprintf(buf, buf_size, "File system not enabled\n");
  }
  return -ENOTSUP;
}
#endif

/* 导出为原始格式 */
int ir_learning_export_raw(const ir_learned_signal_t *signal, char *buf,
                           size_t buf_size) {
  if (!signal || !signal->valid || !buf) {
    return -EINVAL;
  }

  size_t offset = 0;
  offset += snprintf(buf + offset, buf_size - offset, "# IR Signal: %s\n",
                     signal->name);
  offset +=
      snprintf(buf + offset, buf_size - offset, "# Edges: %u, Carrier: %u Hz\n",
               signal->timing_count, signal->carrier_freq);
  offset +=
      snprintf(buf + offset, buf_size - offset, "# Format: duration_us\n");

  for (uint16_t i = 0; i < signal->timing_count && offset < buf_size; i++) {
    offset +=
        snprintf(buf + offset, buf_size - offset, "%u\n", signal->timings[i]);
  }

  return 0;
}

/* 分析信号 */
int ir_learning_analyze(const ir_learned_signal_t *signal,
                        ir_signal_analysis_t *analysis) {
  if (!signal || !signal->valid || !analysis) {
    return -EINVAL;
  }

  memset(analysis, 0, sizeof(ir_signal_analysis_t));

  uint64_t mark_sum = 0, space_sum = 0;
  uint32_t mark_count = 0, space_count = 0;

  analysis->min_pulse = UINT32_MAX;
  analysis->max_pulse = 0;
  analysis->pulse_count = signal->timing_count;

  for (uint16_t i = 0; i < signal->timing_count; i++) {
    uint32_t duration = signal->timings[i];

    if (duration < analysis->min_pulse) {
      analysis->min_pulse = duration;
    }
    if (duration > analysis->max_pulse) {
      analysis->max_pulse = duration;
    }

    if (i % 2 == 0) { // Mark
      mark_sum += duration;
      mark_count++;
    } else { // Space
      space_sum += duration;
      space_count++;
    }
  }

  if (mark_count > 0) {
    analysis->avg_mark = mark_sum / mark_count;
  }
  if (space_count > 0) {
    analysis->avg_space = space_sum / space_count;
  }

  /* 估算载波频率 (基于最短mark脉冲) */
  if (analysis->min_pulse > 0) {
    analysis->estimated_freq = 1000000 / (analysis->min_pulse * 2);
    /* 四舍五入到常见频率 */
    if (analysis->estimated_freq > 35000 && analysis->estimated_freq < 41000) {
      analysis->estimated_freq = 38000;
    } else if (analysis->estimated_freq > 33000 &&
               analysis->estimated_freq < 37000) {
      analysis->estimated_freq = 36000;
    } else if (analysis->estimated_freq > 38000 &&
               analysis->estimated_freq < 42000) {
      analysis->estimated_freq = 40000;
    }
  }

  LOG_INF("Analysis: avg_mark=%u, avg_space=%u, freq=%u Hz", analysis->avg_mark,
          analysis->avg_space, analysis->estimated_freq);

  return 0;
}

/* 比较两个信号 */
int ir_learning_compare(const ir_learned_signal_t *sig1,
                        const ir_learned_signal_t *sig2, uint8_t *similarity) {
  if (!sig1 || !sig2 || !sig1->valid || !sig2->valid || !similarity) {
    return -EINVAL;
  }

  /* 如果长度差异太大，相似度为0 */
  if (abs((int)sig1->timing_count - (int)sig2->timing_count) > 10) {
    *similarity = 0;
    return 0;
  }

  uint32_t min_len = sig1->timing_count < sig2->timing_count
                         ? sig1->timing_count
                         : sig2->timing_count;

  uint32_t matches = 0;
  uint32_t tolerance = 200; // 200us容差

  for (uint32_t i = 0; i < min_len; i++) {
    uint32_t t1 = sig1->timings[i];
    uint32_t t2 = sig2->timings[i];
    uint32_t diff = t1 > t2 ? t1 - t2 : t2 - t1;

    if (diff <= tolerance) {
      matches++;
    }
  }

  *similarity = (matches * 100) / min_len;
  return 0;
}
```

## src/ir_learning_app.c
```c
/**
 * @file ir_learning_app.c
 * @brief IR自学习功能应用示例
 */

#include "ir_learning.h"
#include "ir_service.h"
#include <stdlib.h> // 添加：atoi
#include <string.h> // 添加：strcmp
#include <zephyr/kernel.h>
#include <zephyr/logging/log.h>
#include <zephyr/shell/shell.h>


LOG_MODULE_REGISTER(ir_learn_app, LOG_LEVEL_INF);

/* 学习状态回调 */
static void learning_callback(ir_learn_status_t status,
                              const ir_learned_signal_t *signal,
                              void *user_data) {
  switch (status) {
  case IR_LEARN_IDLE:
    LOG_INF("Learning: Idle");
    break;

  case IR_LEARN_WAITING:
    LOG_INF("Learning: Waiting for signal...");
    LOG_INF("Please press the button on your remote control");
    break;

  case IR_LEARN_RECEIVING:
    LOG_INF("Learning: Receiving signal...");
    break;

  case IR_LEARN_COMPLETED:
    if (signal) {
      LOG_INF("Learning: Completed!");
      LOG_INF("  Name: %s", signal->name);
      LOG_INF("  Edges: %u", signal->timing_count);
      LOG_INF("  Duration: %u us", signal->total_duration_us);

      /* 分析信号 */
      ir_signal_analysis_t analysis;
      if (ir_learning_analyze(signal, &analysis) == 0) {
        LOG_INF("  Analysis:");
        LOG_INF("    Avg mark: %u us", analysis.avg_mark);
        LOG_INF("    Avg space: %u us", analysis.avg_space);
        LOG_INF("    Estimated freq: %u Hz", analysis.estimated_freq);
      }
    }
    break;

  case IR_LEARN_TIMEOUT:
    LOG_WRN("Learning: Timeout - no signal detected");
    break;

  case IR_LEARN_ERROR:
    LOG_ERR("Learning: Error occurred");
    break;
  }
}

/* 自学习测试函数 */
void test_ir_learning(void) {
  LOG_INF("=== IR Learning Test ===");

  /* 1. 初始化 */
  int ret = ir_learning_init();
  if (ret < 0) {
    LOG_ERR("Failed to init learning: %d", ret);
    return;
  }

  /* 2. 学习Power按键 */
  LOG_INF("\n--- Learning 'Power' button ---");
  ret = ir_learning_start("Power", learning_callback, NULL, 10000);
  if (ret < 0) {
    LOG_ERR("Failed to start learning: %d", ret);
    return;
  }

  /* 等待学习完成 */
  k_sleep(K_SECONDS(12));

  /* 3. 如果成功，保存信号 */
  ir_learned_signal_t power_signal;
  memset(&power_signal, 0, sizeof(power_signal));
  power_signal.timings = k_malloc(IR_LEARNING_MAX_EDGES * sizeof(uint32_t));

  /* 这里假设学习成功，实际应该在回调中处理 */

  /* 4. 学习Volume Up */
  LOG_INF("\n--- Learning 'Volume Up' button ---");
  k_sleep(K_SECONDS(2));

  ret = ir_learning_start("VolumeUp", learning_callback, NULL, 10000);
  k_sleep(K_SECONDS(12));

  LOG_INF("\n=== Learning Test Complete ===");
}

#ifdef CONFIG_SHELL

/* Shell命令: learn - 学习新信号 */
static int cmd_learn(const struct shell *sh, size_t argc, char **argv) {
  if (argc < 2) {
    shell_error(sh, "Usage: learn <signal_name> [timeout_ms]");
    return -EINVAL;
  }

  const char *name = argv[1];
  uint32_t timeout = argc > 2 ? atoi(argv[2]) : 5000;

  shell_print(sh, "Starting learning mode...");
  shell_print(sh, "Signal name: %s", name);
  shell_print(sh, "Timeout: %u ms", timeout);
  shell_print(sh, "Point your remote and press the button NOW!");

  int ret = ir_learning_start(name, learning_callback, (void *)sh, timeout);
  if (ret < 0) {
    shell_error(sh, "Failed to start learning: %d", ret);
    return ret;
  }

  return 0;
}

/* Shell命令: replay - 重放学习的信号 */
static int cmd_replay(const struct shell *sh, size_t argc, char **argv) {
  if (argc < 2) {
    shell_error(sh, "Usage: replay <signal_name> [repeat]");
    return -EINVAL;
  }

  const char *name = argv[1];
  uint32_t repeat = argc > 2 ? atoi(argv[2]) : 1;

  /* 从存储加载信号 */
  ir_learned_signal_t signal;
  memset(&signal, 0, sizeof(signal));
  signal.timings = k_malloc(IR_LEARNING_MAX_EDGES * sizeof(uint32_t));

  if (!signal.timings) {
    shell_error(sh, "Memory allocation failed");
    return -ENOMEM;
  }

  int ret = ir_learning_load(&signal, name);
  if (ret < 0) {
    shell_error(sh, "Failed to load signal: %d", ret);
    k_free(signal.timings);
    return ret;
  }

  shell_print(sh, "Replaying: %s (%u times)", name, repeat);

  ret = ir_learning_replay(&signal, repeat);
  k_free(signal.timings);

  if (ret < 0) {
    shell_error(sh, "Replay failed: %d", ret);
    return ret;
  }

  shell_print(sh, "Replay completed");
  return 0;
}

/* Shell命令: save - 保存当前学习的信号 */
#if 0 // 暂时禁用未实现的功能
static int cmd_save(const struct shell *sh, size_t argc, char **argv)
{
    if (argc < 2) {
        shell_error(sh, "Usage: save <name>");
        return -EINVAL;
    }
    
    /* 这里需要访问最近学习的信号 */
    shell_error(sh, "Not implemented - use learning callback to auto-save");
    return -ENOTSUP;
}
#endif

/* Shell命令: list - 列出所有学习的信号 */
static int cmd_list_learned(const struct shell *sh, size_t argc, char **argv) {
  char buf[1024];

  int ret = ir_learning_list(buf, sizeof(buf));
  if (ret < 0) {
    shell_error(sh, "Failed to list signals: %d", ret);
    return ret;
  }

  shell_print(sh, "%s", buf);
  return 0;
}

/* Shell命令: delete - 删除学习的信号 */
static int cmd_delete(const struct shell *sh, size_t argc, char **argv) {
  if (argc < 2) {
    shell_error(sh, "Usage: delete <signal_name>");
    return -EINVAL;
  }

  const char *name = argv[1];

  int ret = ir_learning_delete(name);
  if (ret < 0) {
    shell_error(sh, "Failed to delete: %d", ret);
    return ret;
  }

  shell_print(sh, "Signal deleted: %s", name);
  return 0;
}

/* Shell命令: analyze - 分析信号 */
static int cmd_analyze(const struct shell *sh, size_t argc, char **argv) {
  if (argc < 2) {
    shell_error(sh, "Usage: analyze <signal_name>");
    return -EINVAL;
  }

  const char *name = argv[1];

  /* 加载信号 */
  ir_learned_signal_t signal;
  memset(&signal, 0, sizeof(signal));
  signal.timings = k_malloc(IR_LEARNING_MAX_EDGES * sizeof(uint32_t));

  if (!signal.timings) {
    shell_error(sh, "Memory allocation failed");
    return -ENOMEM;
  }

  int ret = ir_learning_load(&signal, name);
  if (ret < 0) {
    shell_error(sh, "Failed to load signal: %d", ret);
    k_free(signal.timings);
    return ret;
  }

  /* 分析 */
  ir_signal_analysis_t analysis;
  ret = ir_learning_analyze(&signal, &analysis);

  if (ret == 0) {
    shell_print(sh, "Signal Analysis: %s", name);
    shell_print(sh, "  Pulse count: %u", analysis.pulse_count);
    shell_print(sh, "  Avg mark: %u us", analysis.avg_mark);
    shell_print(sh, "  Avg space: %u us", analysis.avg_space);
    shell_print(sh, "  Min pulse: %u us", analysis.min_pulse);
    shell_print(sh, "  Max pulse: %u us", analysis.max_pulse);
    shell_print(sh, "  Estimated carrier: %u Hz", analysis.estimated_freq);
  }

  k_free(signal.timings);
  return ret;
}

/* Shell命令: compare - 比较两个信号 */
static int cmd_compare(const struct shell *sh, size_t argc, char **argv) {
  if (argc < 3) {
    shell_error(sh, "Usage: compare <signal1> <signal2>");
    return -EINVAL;
  }

  ir_learned_signal_t sig1, sig2;
  memset(&sig1, 0, sizeof(sig1));
  memset(&sig2, 0, sizeof(sig2));

  sig1.timings = k_malloc(IR_LEARNING_MAX_EDGES * sizeof(uint32_t));
  sig2.timings = k_malloc(IR_LEARNING_MAX_EDGES * sizeof(uint32_t));

  if (!sig1.timings || !sig2.timings) {
    shell_error(sh, "Memory allocation failed");
    if (sig1.timings)
      k_free(sig1.timings);
    if (sig2.timings)
      k_free(sig2.timings);
    return -ENOMEM;
  }

  /* 加载两个信号 */
  int ret1 = ir_learning_load(&sig1, argv[1]);
  int ret2 = ir_learning_load(&sig2, argv[2]);

  if (ret1 < 0 || ret2 < 0) {
    shell_error(sh, "Failed to load signals");
    k_free(sig1.timings);
    k_free(sig2.timings);
    return -EINVAL;
  }

  /* 比较 */
  uint8_t similarity;
  int ret = ir_learning_compare(&sig1, &sig2, &similarity);

  if (ret == 0) {
    shell_print(sh, "Comparing: %s vs %s", argv[1], argv[2]);
    shell_print(sh, "Similarity: %u%%", similarity);

    if (similarity > 90) {
      shell_print(sh, "Result: Signals are nearly identical");
    } else if (similarity > 70) {
      shell_print(sh, "Result: Signals are similar");
    } else if (similarity > 50) {
      shell_print(sh, "Result: Signals have some similarities");
    } else {
      shell_print(sh, "Result: Signals are different");
    }
  }

  k_free(sig1.timings);
  k_free(sig2.timings);
  return ret;
}

/* Shell命令: export - 导出信号为文本格式 */
static int cmd_export(const struct shell *sh, size_t argc, char **argv) {
  if (argc < 2) {
    shell_error(sh, "Usage: export <signal_name>");
    return -EINVAL;
  }

  const char *name = argv[1];

  /* 加载信号 */
  ir_learned_signal_t signal;
  memset(&signal, 0, sizeof(signal));
  signal.timings = k_malloc(IR_LEARNING_MAX_EDGES * sizeof(uint32_t));

  if (!signal.timings) {
    shell_error(sh, "Memory allocation failed");
    return -ENOMEM;
  }

  int ret = ir_learning_load(&signal, name);
  if (ret < 0) {
    shell_error(sh, "Failed to load signal: %d", ret);
    k_free(signal.timings);
    return ret;
  }

  /* 导出 */
  char *export_buf = k_malloc(8192);
  if (export_buf) {
    ir_learning_export_raw(&signal, export_buf, 8192);
    shell_print(sh, "%s", export_buf);
    k_free(export_buf);
  }

  k_free(signal.timings);
  return 0;
}

/* 学习命令组 */
SHELL_STATIC_SUBCMD_SET_CREATE(
    learn_cmds, SHELL_CMD(learn, NULL, "Learn a new signal", cmd_learn),
    SHELL_CMD(replay, NULL, "Replay learned signal", cmd_replay),
    SHELL_CMD(list, NULL, "List learned signals", cmd_list_learned),
    SHELL_CMD(delete, NULL, "Delete learned signal", cmd_delete),
    SHELL_CMD(analyze, NULL, "Analyze signal", cmd_analyze),
    SHELL_CMD(compare, NULL, "Compare two signals", cmd_compare),
    SHELL_CMD(export, NULL, "Export signal to raw format", cmd_export),
    SHELL_SUBCMD_SET_END);

SHELL_CMD_REGISTER(irlearn, &learn_cmds, "IR learning commands", NULL);

#endif /* CONFIG_SHELL */
```
